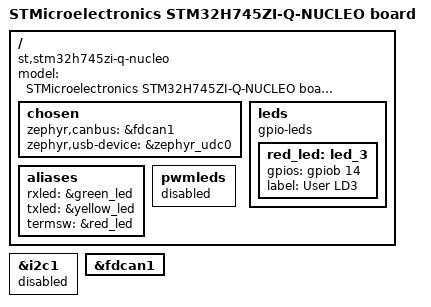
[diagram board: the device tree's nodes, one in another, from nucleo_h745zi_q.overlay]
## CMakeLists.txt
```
# SPDX-License-Identifier: Apache-2.0

cmake_minimum_required(VERSION 3.20.0)

find_package(Zephyr REQUIRED HINTS $ENV{ZEPHYR_BASE})
project(gs_usb_example)

target_sources(app PRIVATE src/main.c)
```

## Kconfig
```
# Private config options for can sample app

# Copyright (c) 2018 Alexander Kozhinov
# SPDX-License-Identifier: Apache-2.0

mainmenu "gs_usb sample application"

source "Kconfig.zephyr"
```

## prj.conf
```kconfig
CONFIG_CAN=y
CONFIG_NET_L2_ETHERNET=n
CONFIG_CAN_MAX_FILTER=5

CONFIG_NETWORKING=y
CONFIG_NET_DRIVERS=y
CONFIG_NET_CANBUS=y
CONFIG_NET_SOCKETS=y
CONFIG_NET_SOCKETS_CAN=y
CONFIG_POSIX_API=y

CONFIG_NET_IPV6=n
CONFIG_NET_IPV4=n
CONFIG_NET_MGMT=n
CONFIG_NET_TCP=n
CONFIG_NET_UDP=n

CONFIG_NET_DEFAULT_IF_CANBUS_RAW=y

CONFIG_NET_PKT_RX_COUNT=30
CONFIG_NET_PKT_TX_COUNT=30
CONFIG_NET_BUF_RX_COUNT=30
CONFIG_NET_BUF_TX_COUNT=30

CONFIG_TEST_RANDOM_GENERATOR=y

CONFIG_LOG=y
CONFIG_NET_LOG=y

CONFIG_NET_SOCKETS_LOG_LEVEL_DBG=n
CONFIG_CAN_LOG_LEVEL_DBG=n
CONFIG_GS_USB_LOG_LEVEL_DBG=y
CONFIG_GS_USB_TERM_PIN=y
# CONFIG_NET_CONTEXT_LOG_LEVEL_DBG=n
# CONFIG_NET_CORE_LOG_LEVEL_DBG=n
# CONFIG_NET_CONN_LOG_LEVEL_DBG=n

# Use smaller buffers for net_buf as CANBUS packets are quite small.
CONFIG_NET_BUF_DATA_SIZE=64

CONFIG_CAN_FD_MODE=n
CONFIG_CAN_RX_TIMESTAMP=y

CONFIG_LOG_BUFFER_SIZE=32768

# USB related configs
CONFIG_USB_GS_USB_CLASS=y
CONFIG_USB_REQUEST_BUFFER_SIZE=2048

CONFIG_USB_DEVICE_STACK=y
CONFIG_USB_DEVICE_PRODUCT="Zephyr gs_usb"
CONFIG_USB_DEVICE_VID=0x1d50
CONFIG_USB_DEVICE_PID=0x606f
CONFIG_USB_DEVICE_INITIALIZE_AT_BOOT=n
CONFIG_USB_DRIVER_LOG_LEVEL_DBG=n
CONFIG_USB_DEVICE_LOG_LEVEL_DBG=n

CONFIG_SHELL=y
CONFIG_CAN_SHELL=y
CONFIG_CAN_SHELL_SCRIPTING_FRIENDLY=y
```

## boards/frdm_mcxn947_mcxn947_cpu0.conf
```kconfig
CONFIG_CAN_FD_MODE=y
CONFIG_LOG=y

CONFIG_GS_USB_CAN_TX_MSG_QUEUE_SIZE=80
CONFIG_GS_USB_CAN_RX_MSG_QUEUE_SIZE=80
```

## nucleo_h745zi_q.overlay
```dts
/*
 * Copyright (c) 2024 Alexander Kozhinov <ak.alexander.kozhinov@gmail.com>
 *
 * SPDX-License-Identifier: Apache-2.0
 */

/ {
	model = "STMicroelectronics STM32H745ZI-Q-NUCLEO board";
	compatible = "st,stm32h745zi-q-nucleo";

	chosen {
		zephyr,canbus = &fdcan1;
		zephyr,usb-device = &zephyr_udc0;
	};

	leds: leds {
		compatible = "gpio-leds";
		red_led: led_3 {
			gpios = <&gpiob 14 GPIO_ACTIVE_HIGH>;
			label = "User LD3";
		};
	};

	aliases {
		rxled = &green_led;
		txled = &yellow_led;
		termsw = &red_led;
	};

	pwmleds {
		status = "disabled";
	};
};

&i2c1 {
	status = "disabled";
};

&fdcan1 {
	status = "okay";
};
```

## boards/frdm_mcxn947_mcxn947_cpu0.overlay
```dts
/*
 * Copyright (c) 2024 Alexander Kozhinov <ak.alexander.kozhinov@gmail.com>
 *
 * SPDX-License-Identifier: Apache-2.0
 */

/ {
	model = "STMicroelectronics STM32H745ZI-Q-NUCLEO board";
	compatible = "st,stm32h745zi-q-nucleo";

	chosen {
		zephyr,canbus = &flexcan_fd0;
		zephyr,usb-device = &zephyr_udc0;
	};


	aliases {
		rxled = &green_led;
		txled = &blue_led;
		termsw = &red_led;
	};

	pwmleds {
		status = "disabled";
	};
};
```

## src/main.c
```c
/*
 * Copyright (c) 2024 Alexander Kozhinov
 *
 * SPDX-License-Identifier: Apache-2.0
 */

#include <zephyr/logging/log.h>
LOG_MODULE_REGISTER(gs_usb_can_sample, CONFIG_GS_USB_LOG_LEVEL);

#include <zephyr/kernel.h>

#include <zephyr/usb/usb_device.h>
#include <zephyr/usb/class/gs_usb.h>
#include <zephyr/drivers/gpio.h>


int main(void)
{
	int ret = 0;
	const struct device *can_dev = DEVICE_DT_GET(DT_CHOSEN(zephyr_canbus));

	ret = device_is_ready(can_dev);
	if (!ret) {
		printk("CAN: Device %s not ready.\n", can_dev->name);
		return ret;
	}

	const struct gpio_dt_spec rx_led = GPIO_DT_SPEC_GET(DT_ALIAS(rxled), gpios);
	ret = gpio_is_ready_dt(&rx_led);
	if (!ret) {
		printk("rx_led device not ready\n");
		return ret;
	}

	const struct gpio_dt_spec tx_led = GPIO_DT_SPEC_GET(DT_ALIAS(txled), gpios);
	ret = gpio_is_ready_dt(&tx_led);
	if (!ret) {
		printk("tx_led device not ready\n");
		return ret;
	}

	const struct gpio_dt_spec term_sw = GPIO_DT_SPEC_GET(DT_ALIAS(termsw), gpios);
	ret = gpio_is_ready_dt(&term_sw);
	if (!ret) {
		printk("termsw device not ready\n");
		return ret;
	}

	ret = gs_usb_init(can_dev, &rx_led, &tx_led, &term_sw);
	if (ret != 0) {
		LOG_ERR("Failed to initialize gs_usb");
		return ret;
	}

	ret = gs_usb_start(0);
	if (ret != 0) {
		LOG_ERR("Failed to start gs_usb");
		return ret;
	}

	k_sleep(K_FOREVER);
	return ret;
}
```
